# iND83213A register map
Vendor: Indiemicro; Series: Rugby; File version: 1.0
CPU: CM0 r0p1, selectable endian, no MPU, no FPU, 4 interrupt priority bits
Registers are 32-bit, read-write, no defined reset value unless marked. A register's access mark holds for its fields unless they carry their own. Offsets are from the block's base; [hi:lo] are bit positions; {n}, {i} and the like mark numbered series.

## BUCK_INF — BUCK Interface Registers
Base 0x50010500; register names take the prefix BUCK_INF_
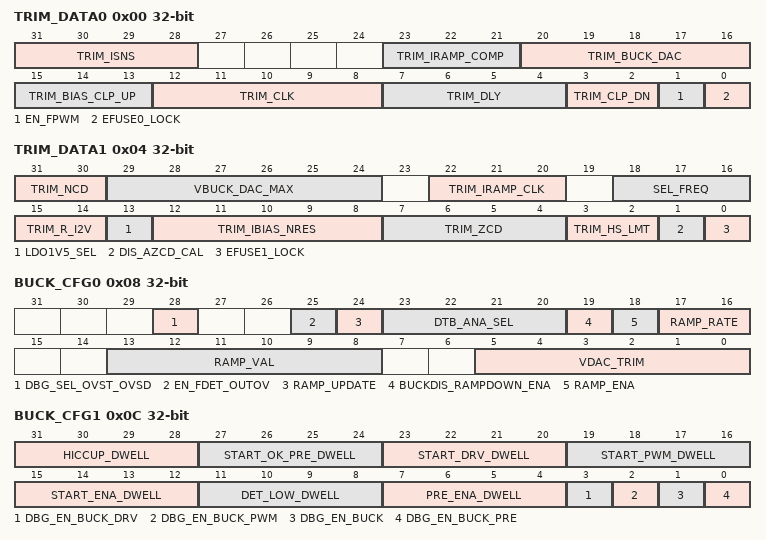
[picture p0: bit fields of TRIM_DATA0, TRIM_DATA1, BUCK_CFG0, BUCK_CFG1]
0x00 TRIM_DATA0
  [31:28] TRIM_ISNS — Trim the offset current of HS current sensor. 0x0: 94.18uA 0x1: 97.51uA 0x2: 100.01uA 0x3: 103.5uA 0x4: 105.5uA 0x5: 108.8uA 0x6: 111.4uA 0x7: 114.7uA 0x8: 71.64uA 0x9: 74.97uA 0xa: 77.6uA 0xb: 80.94uA 0xc: 82.92uA 0xd: 86.25uA 0xe: 88.88uA 0xf: 92.21uA
  [23:21] TRIM_IRAMP_COMP — Trim the current which generates compensation ramp.
  [20:16] TRIM_BUCK_DAC — Trim BUCK dac precision.
  [15:13] TRIM_BIAS_CLP_UP — Trim clamp up bias. 40K ohms clamp up reference resistor add in IR each step.(TBD)
  [12:8] TRIM_CLK — Trim internal BUCK clock(2Mhz/400Khz).
  [7:4] TRIM_DLY — Trim delay time for better accuracy.
  [3:2] TRIM_CLP_DN — Clamp down voltage for VC_EA. 0x0: 400mV 0x1: 500mV 0x2: 600mV 0x3: 700mV
  [1] EN_FPWM — Enable force PWM option.
  [0] EFUSE0_LOCK — The lock signal of eFUSE0. EFUSE0 lock signal can be read out from bitcell at EFUSE0 address 0(after programming). When efuse_lock becomes 1, the programming mode is forbidden and the read data from EFUSE0 can be update to the corresponding registers.
0x04 TRIM_DATA1
  [31:30] TRIM_NCD — Trim the threshold current for NCD. 0x0: -854mA 0x1: -1.434A 0x2: -1.434A 0x3: -1.984A
  [29:24] VBUCK_DAC_MAX — Set maximum output voltage code of BUCK. The BUCK dac code is range from 0 to VBUCK_DAC_MAX.
  [22:20] TRIM_IRAMP_CLK — TRIM_IRAMP_CLK. Trim the bias current send to compensation current ramp module.
  [18:16] SEL_FREQ — Set BUCK clock frequency. 3'b000: 2.125Mhz 3'b001: 1.15Mhz 3'b010: 800Khz 3'b011: 600Khz 3'b100: 490Khz 3'b101: 400Khz others: 2.125Mhz
  [15:14] TRIM_R_I2V — Trim the resistance of I to V sampling circuit. 0x0: 2.5k ohm 0x1: 5k ohm 0x2: 7.5k ohm 0x3: 10k ohm
  [13] LDO1V5_SEL — Select 1p5v ldo type. 1'b0:cap 1p5v LDO. 1'b1:capless 1p5v LDO.
  [12:8] TRIM_IBIAS_NRES — Trim the current which is not related to the process corner of resistance.
  [7:4] TRIM_ZCD — Trim the offset voltage of ZCD comparator. 0x0: -23.45mV 0x1: -21.55mV 0x2: -19.75mV 0x3: -17.85mV 0x4: -15.95mV 0x5: -14.05mV 0x6: -12.15mV 0x7: -10.25mV 0x8: -8.35mV 0x9: -6.45mV 0xa: -4.55mV 0xb: -2.65mV 0xc: -750uV 0xd: 1.15mV 0xe: 3.05mV 0xf: 4.95mV
  [3:2] TRIM_HS_LMT — Trim the current limit of high side NMOS. 0x0: 1.812A 0x1: 2.122A 0x2: 2.422A 0x3: 2.712A
  [1] DIS_AZCD_CAL — Disable auto zcd calculation. 1'b0: enable auto zcd calculation. 1'b1:disable auto zcd calculation.
  [0] EFUSE1_LOCK — The lock signal of eFUSE1. EFUSE1 lock signal can be read out from bitcell at EFUSE1 address 0(after programming). When efuse_lock becomes 1, the programming mode is forbidden and the read data from EFUSE1 can be update to the corresponding registers.
0x08 BUCK_CFG0 — BUCK configuration register0
  [28] DBG_SEL_OVST_OVSD — Control BUCK vout ov threshold in debug mode. 1'b0: 1.1 times of output voltage set value; 1'b1: 2.5V.
  [25] EN_FDET_OUTOV — Force enable VOUT OVP detect in BUCK auto mode. 1'b0: Don't force and VOUT OVP detect comparator will turn off in PS mode. 1'b1: Force enable VOUT OVP detect comparator.
  [24] RAMP_UPDATE — Update VDAC ramp parameters. Set high then set low to launch a ramp update.
  [23:20] DTB_ANA_SEL — select for DTB. Select Analog observed signal to DTB[1]. 0x0: PWM_COMP_OUT 0x1: VBTPORN_ST 0x2: CLP_L_ST 0x3: ZCD_COMP_OUT 0x4: LS_ILMT_ST 0x5: HS_ILMT_ST 0x6: LS_ON_ST 0x7: HS_ON_ST 0x8: VOUT_SHORT_ST 0x9: VOUT_SOFT_OK_ST 0xa: VOUT_OVP_ST 0xb: VIN_UVLO_ST 0xc: VOUT_SD_LOW_N 0xd: PFM_PS 0xe: DTB_RC_PULAE 0xf: CLK_DIV2
  [19] BUCKDIS_RAMPDOWN_ENA — Enable of Ramp down after Core Buck disable. set 1'b1 to enable
  [18] RAMP_ENA — Enable the Ramp feature for VDAC. If set enables the core to ramp the VDAC at a rate set by RAMP_RATE, till the VDAC reach the set code in VDAC_TRIM. if set to '1 the ramped value will be available on VDAC bus, if set to '0 the vdac_trim will be available on VDAC bus
  [17:16] RAMP_RATE — VDAC ramp rate to reach to VDAC_TRIM. When RAMP_ENA is set, the register decides the rate at which the VDAC ramp up/down to reach the set VDAC_TRIM 0x0: 7.8us per step 0x1: 15.6us per step 0x2: 31.2us per step 0x3: 62.4us per step
  [13:8] RAMP_VAL — VDAC ramp start code. The register can only be set in buck debug mode.
  [5:0] VDAC_TRIM — TRIM code for VDAC. Set the VDAC trim code, which decides BUCK output voltage. VBUCK_OUT = (0.15625*VDAC_TRIM) V. The trim code is range from 0 to VBUCK_DAC_MAX. If the trim code is bigger than VBUCK_DAC_MAX, the trim code would be forced to VBUCK_DAC_MAX.
0x0C BUCK_CFG1 — BUCK configuration register1
  [31:28] HICCUP_DWELL — HICCUP Timeout Setting. Timeout wait time = (HICCUP_DWELL + 1)*1ms.
  [27:24] START_OK_PRE_DWELL — START_OK_PRE Timeout Setting. Timeout wait time = (START_OK_PRE_DWELL + 1)*(2^RAMP_RATE)*31.2us.
  [23:20] START_DRV_DWELL — START_DRV Timeout Setting. Timeout wait time = (START_DRV_DWELL + 1)*(2^RAMP_RATE)*7.8us.
  [19:16] START_PWM_DWELL — START_PWM Timeout Setting. Timeout wait time = (START_PWM_DWELL + 1)*7.8us.
  [15:12] START_ENA_DWELL — START_ENA Timeout Setting. Timeout wait time = (START_ENA_DWELL + 1)*7.8us.
  [11:8] DET_LOW_DWELL — DET_LOW Timeout Setting. Timeout wait time = (DET_LOW_DWELL + 1)*1ms.
  [7:4] PRE_ENA_DWELL — PRE_ENA Timeout Setting. Timeout wait time = (PRE_ENA_DWELL + 1)*3.9us.
  [3] DBG_EN_BUCK_DRV — BUCK enable of power stage and driver in debug mode. Set 1'b1 to enable.
  [2] DBG_EN_BUCK_PWM — BUCK enable of PWM Logic in debug mode. Set 1'b1 to enable.
  [1] DBG_EN_BUCK — BUCK control enable in debug mode. Set 1'b1 to enable.
  [0] DBG_EN_BUCK_PRE — Enable V-I and comp_top to detect errors in debug mode. Set 1'b1 to enable.
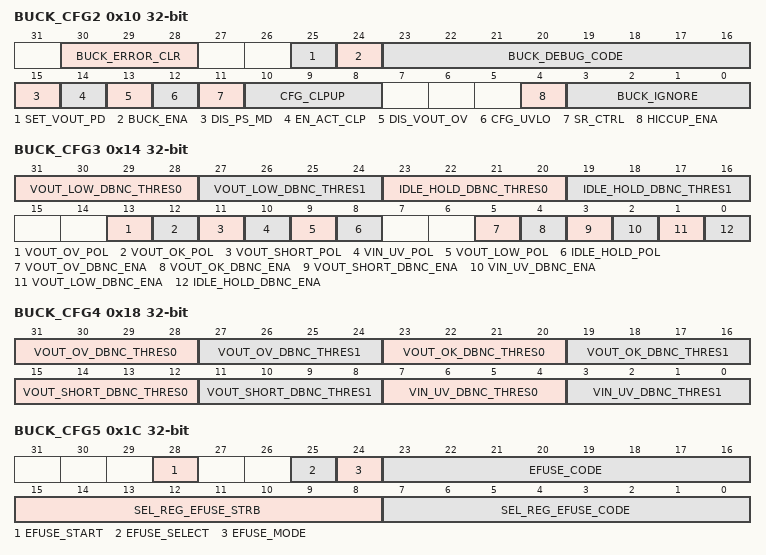
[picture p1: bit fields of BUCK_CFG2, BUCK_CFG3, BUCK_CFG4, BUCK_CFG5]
0x10 BUCK_CFG2 — BUCK configuration register2
  [30:28] BUCK_ERROR_CLR — BUCK error flag clear. Set high then set low to launch a clear operation. BIT[0] : clear error flag: VOUT OVP can't release before BUCK startup BIT[1] : clear error flag: VOUT SHORT can't release after BUCK startup for a while BIT[2] : clear error flag: Vout OK detect fail
  [25] SET_VOUT_PD — SET_VOUT_PD. Set 1 to pull down BUCK output.
  [24] BUCK_ENA — BUCK enable request. Setting this bit to '1 will kickstart the statup sequence for the buck regulator. Setting this bit to '0 will start the off sequence for the buck regulator. Auto clearred if hiccup is disabled & error conditions are encountered.
  [23:16] BUCK_DEBUG_CODE — Code used to set debug mode of BUCK control module. Write 0x2C to this register to enable debug mode. Write any other value to disable the debug mode.
  [15] DIS_PS_MD — Disable pfm_ps_st2 output. 1'b0: the output value of pfm_ps_st2 is valid; 1'b1: the output value of pfm_ps_st2 is set to 0.
  [14] EN_ACT_CLP — Set active clamp down option. 1'b0: enable active clamp down.1'b1: disable active clamp down. The register can only be set in buck debug mode.
  [13] DIS_VOUT_OV — Set VOUT OV option. 1'b0: enable VOUT OV detection.1'b1: disable VOUT OV detection
  [12] CFG_UVLO — Set UVLO threshold. 1'b0: VIN UVLO=4V.1'b1: VIN UVLO=6V
  [11] SR_CTRL — Set slew rate.
  [10:8] CFG_CLPUP — Set clamp up configuration.
  [4] HICCUP_ENA — BUCK HICCUP Enable. Set this bit to high will enable the hiccup control of BUCK FSM.
  [3:0] BUCK_IGNORE — BUCK Status ignore. BIT[0] : ignore vin uvlo detection BIT[1] : ignore vout low detection BIT[2] : ignore vout short detection BIT[3] : ignore vout ok detection
0x14 BUCK_CFG3 — BUCK configuration register3
  [31:28] VOUT_LOW_DBNC_THRES0 — VOUT_LOW debounce threshold from 1 to 0. The deglitch width to detect 0 is from 62.4us to 998.4us.
  [27:24] VOUT_LOW_DBNC_THRES1 — VOUT_LOW debounce threshold from 0 to 1. The deglitch width to detect 1 is from 62.4us to 998.4us.
  [23:20] IDLE_HOLD_DBNC_THRES0 — IDLE_HOLD debounce threshold from 1 to 0. The deglitch width to detect 0 is from 3.9us to 62.4us.
  [19:16] IDLE_HOLD_DBNC_THRES1 — IDLE_HOLD debounce threshold from 0 to 1. The deglitch width to detect 1 is from 3.9us to 62.4us.
  [13] VOUT_OV_POL — The valid level polarity for BUCK VOUT OV signal. 1'b0: the valid level polarity is high. 1'b1: the valid level polarity is low.
  [12] VOUT_OK_POL — The valid level polarity for BUCK VOUT OK signal. 1'b0: the valid level polarity is high. 1'b1: the valid level polarity is low.
  [11] VOUT_SHORT_POL — The valid level polarity for BUCK VOUT SHORT signal. 1'b0: the valid level polarity is high. 1'b1: the valid level polarity is low.
  [10] VIN_UV_POL — The valid level polarity for BUCK VIN UVLO signal. 1'b0: the valid level polarity is high. 1'b1: the valid level polarity is low.
  [9] VOUT_LOW_POL — The valid level polarity for BUCK VOUT LOW signal. 1'b0: the valid level polarity is high. 1'b1: the valid level polarity is low.
  [8] IDLE_HOLD_POL — The valid level polarity for IDLE_HOLD signal. 1'b0: the valid level polarity is high. 1'b1: the valid level polarity is low.
  [5] VOUT_OV_DBNC_ENA — VOUT_OV debounce enable. 1'b0: disable VOUT_OV debounce function. 1'b1: enable VOUT_OV debounce function.
  [4] VOUT_OK_DBNC_ENA — VOUT_OK debounce enable. 1'b0: disable VOUT_OK debounce function. 1'b1: enable VOUT_OK debounce function.
  [3] VOUT_SHORT_DBNC_ENA — VOUT_SHORT debounce enable. 1'b0: disable VOUT_SHORT debounce function. 1'b1: enable VOUT_SHORT debounce function.
  [2] VIN_UV_DBNC_ENA — VIN_UV debounce enable. 1'b0: disable VIN UVLO debounce function. 1'b1: enable VIN UVLO debounce function.
  [1] VOUT_LOW_DBNC_ENA — VOUT_LOW debounce enable. 1'b0: disable VOUT_LOW debounce function. 1'b1: enable VOUT_LOW debounce function.
  [0] IDLE_HOLD_DBNC_ENA — IDLE_HOLD debounce enable. 1'b0: disable IDLE_HOLD debounce function. 1'b1: enable IDLE_HOLD debounce function.
0x18 BUCK_CFG4 — BUCK configuration register4
  [31:28] VOUT_OV_DBNC_THRES0 — VOUT_OV debounce threshold from 1 to 0. The deglitch width to detect 0 is from 7.8us to 124.8us.
  [27:24] VOUT_OV_DBNC_THRES1 — VOUT_OV debounce threshold from 0 to 1. The deglitch width to detect 1 is from 31.2us to 499.2us.
  [23:20] VOUT_OK_DBNC_THRES0 — VOUT_OK debounce threshold from 1 to 0. The deglitch width to detect 0 is from 7.8us to 124.8us.
  [19:16] VOUT_OK_DBNC_THRES1 — VOUT_OK debounce threshold from 0 to 1. The deglitch width to detect 1 is from 7.8us to 124.8us.
  [15:12] VOUT_SHORT_DBNC_THRES0 — VOUT_SHORT debounce threshold from 1 to 0. The deglitch width to detect 0 is from 3.9us to 62.4us.
  [11:8] VOUT_SHORT_DBNC_THRES1 — VOUT_SHORT debounce threshold from 0 to 1. The deglitch width to detect 1 is from 31.2us to 499.2us.
  [7:4] VIN_UV_DBNC_THRES0 — VIN_UV debounce threshold from 1 to 0. The deglitch width to detect 0 is from 249.6us to 3993.6us.
  [3:0] VIN_UV_DBNC_THRES1 — VIN_UV debounce threshold from 0 to 1. The deglitch width to detect 1 is from 3.9us to 62.4us.
0x1C BUCK_CFG5 — BUCK configuration register5
  [28] EFUSE_START — Start EFUSE programming or read/sensing. Set high then set low to launch an EFUSE operation.
  [25] EFUSE_SELECT — EFUSE_SELECT. Select different EFUSE macro(There are two 32 bits EFUSE macros in the chip). 1'b0: EFUSE macro0; 1'b1: EFUSE macro1.
  [24] EFUSE_MODE — EFUSE_MODE. Select EFUSE operation mode.1'b0: read/sensing mode; 1'b1: programming mode.
  [23:16] EFUSE_CODE — Code used to set EFUSE configurate enable. Write 0xB9 to this register to enable EFUSE configuration. Write any other value to disable EFUSE configuration.
  [15:8] SEL_REG_EFUSE_STRB — The register is used to set byte strobe signal to select trim data source when SEL_REG_EFUSE_CODE is set to 0xE2. When SEL_REG_EFUSE_CODE is set to 0xE2 and the corresponding bit is set to high, the byte lane of trim data would come from registers. SEL_REG_EFUSE_STRB[0] corresponds to efuse0 data[ 7: 0]. SEL_REG_EFUSE_STRB[1] corresponds to efuse0 data[15: 8]. SEL_REG_EFUSE_STRB[2] corresponds to efuse0 data[23:16]. SEL_REG_EFUSE_STRB[3] corresponds to efuse0 data[31:24]. SEL_REG_EFUSE_STRB[4] corresponds to efuse1 data[ 7: 0]. SEL_REG_EFUSE_STRB[5] corresponds to efuse1 data[15: 8]. SEL_REG_EFUSE_STRB[6] corresponds to efuse1 data[23:16]. SEL_REG_EFUSE_STRB[7] corresponds to efuse1 data[31:24].
  [7:0] SEL_REG_EFUSE_CODE — Code used to set BUCK trim data sources. Write 0xE2 to this register to select BUCK trim data from registers. Write any other value to select BUCK trim data from EFUSE.
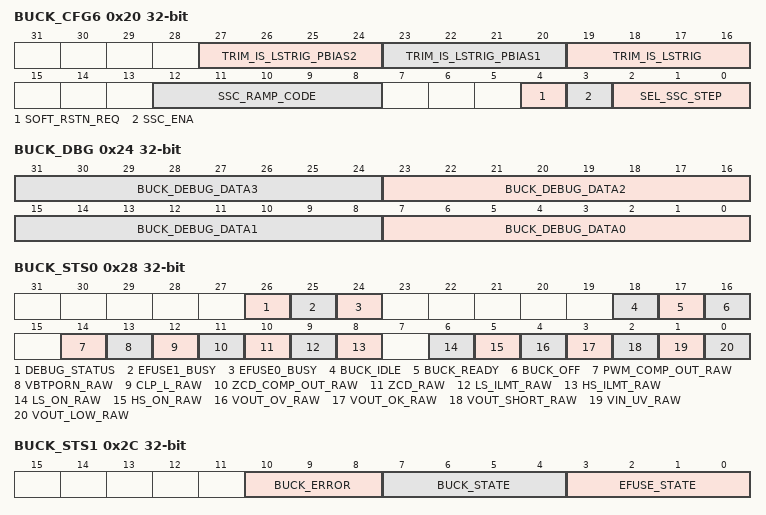
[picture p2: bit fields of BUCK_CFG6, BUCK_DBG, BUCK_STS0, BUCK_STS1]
0x20 BUCK_CFG6 — BUCK configuration register6
  [27:24] TRIM_IS_LSTRIG_PBIAS2 — Trim the upper limit of the curve of LS current limit vs VEA-VCP_L.
  [23:20] TRIM_IS_LSTRIG_PBIAS1 — Trim the upper limit of the curve of LS current limit vs VEA-VCP_L.
  [19:16] TRIM_IS_LSTRIG — Trim the derivative of the curve of LS current limit vs VEA-VCP_L.
  [12:8] SSC_RAMP_CODE — Set SSC ramp code in debug mode. The register can directly control buck clock freq.
  [4] SOFT_RSTN_REQ — Generate a pulse used to reset BUCK 5V logic. Pull up and then pull down to generate a pulse.
  [3] SSC_ENA — SSC enable.
  [2:0] SEL_SSC_STEP — Set step period used in SSC. 3'b000: 8 steps per period . 3'b001: 4 steps per period . 3'b010: 2 steps per period . 3'b011: 1 steps per period . 3'b100: 1 step per 2 periods . 3'b101: 1 step per 3 periods . 3'b110: 1 step per 4 periods . 3'b111: 1 step per 5 periods .
0x24 BUCK_DBG — BUCK debug register
  [8n+7:8n] BUCK_DEBUG_DATA{n} (n=0..3) — Debug signal, only can be set in debug mode.
0x28 BUCK_STS0 — BUCK status register0
  [26] DEBUG_STATUS ro — DEBUG_STATUS. Status of Debug
  [25] EFUSE1_BUSY ro — EFUSE1 busy signal. When EFUSE_BUSY1 becomes 1, EFUSE1 is working in read(sensing)/programming operation mode.
  [24] EFUSE0_BUSY ro — EFUSE0 busy signal. When EFUSE_BUSY0 becomes 1, EFUSE0 is working in read(sensing)/programming operation mode.
  [18] BUCK_IDLE ro — Status of Buck idle. When BUCK_IDLE becomes 1, The FSM of BUCK is located in IDLE state.
  [17] BUCK_READY ro — Status of Buck ready. When BUCK_READY becomes 1, The FSM of BUCK is located in START_OK/ENA_L state.
  [16] BUCK_OFF ro — Status of Buck off. When BUCK_OFF becomes 1, The FSM of BUCK is located in IDLE/HICCUP/PRE_ENA/DET_VIN/DET_LOW/ENA_L_ERR state.
  [14] PWM_COMP_OUT_RAW ro — Raw status of Buck PWM Comparator output.
  [13] VBTPORN_RAW ro — Raw status of voltage for VBT.
  [12] CLP_L_RAW ro — Raw status of clamp low for EA.
  [11] ZCD_COMP_OUT_RAW ro — Raw status of ZCD comparator output.
  [10] ZCD_RAW ro — Raw status of Buck Low Side NMOS is reach to zero current.
  [9] LS_ILMT_RAW ro — Raw status of Buck Low Side NMOS Over Current.
  [8] HS_ILMT_RAW ro — Raw status of Buck High Side NMOS Over Current.
  [6] LS_ON_RAW ro — Raw status of Buck Low Side NMOS ON.
  [5] HS_ON_RAW ro — Raw status of Buck High Side NMOS ON.
  [4] VOUT_OV_RAW ro — Raw status of Buck Output over-voltage.
  [3] VOUT_OK_RAW ro — Raw status of Buck Output voltage OK.
  [2] VOUT_SHORT_RAW ro — Raw status of Buck Output short.
  [1] VIN_UV_RAW ro — Raw status of Buck Input UVLO.
  [0] VOUT_LOW_RAW ro — Raw status of Buck output low.
0x2C BUCK_STS1 — BUCK status register1
  [10:8] BUCK_ERROR ro — BUCK error flag. bit[0] : VOUT OVP can't release before BUCK startup. bit[1] : VOUT SHORT can't release after BUCK startup for a while. bit[2] : VOUT OK detect fail.
  [7:4] BUCK_STATE ro — BUCK FSM state. BUCK FSM state, which can be used for debug. 0x0: IDLE 0x1: HICCUP 0x2: PRE_ENA 0x3: DET_VIN 0x4: DET_LOW 0x5: START_ENA 0x6: START_PWM 0x7: START_DRV 0x8: START_OK_PRE 0x9: START_OK 0xa: ENA_L 0xb: ENA_L_ERR
  [3:0] EFUSE_STATE ro — EFUSE FSM state. EFUSE FSM state, which can be used for debug. 0x0: IDLE 0x1: PG_PSTP1 0x2: PG_PSTP2 0x3: PG_PAS 0x4: PG_WDH 0x5: PG_PAH 0x6: PG_PHD2 0x7: PG_PHD1 0x8: RS_CSSTP 0x9: RS_PRSTP 0xa: RS_PRHD 0xb: RS_SNHD 0xc: RS_CSHD
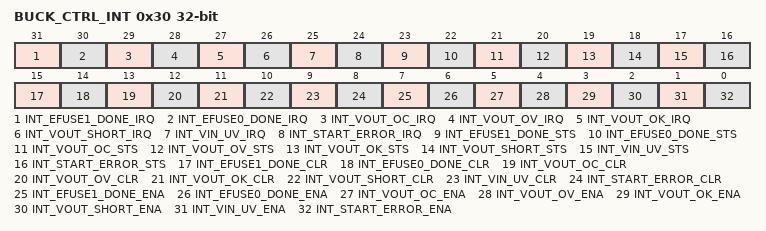
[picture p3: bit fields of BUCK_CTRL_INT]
0x30 BUCK_CTRL_INT — BUCK control & interrupt register
  [31] INT_EFUSE1_DONE_IRQ ro — EFUSE macro1 done interrupt activity.
  [30] INT_EFUSE0_DONE_IRQ ro — EFUSE macro0 done interrupt activity.
  [29] INT_VOUT_OC_IRQ ro — Vout over-current interrupt activity.
  [28] INT_VOUT_OV_IRQ ro — Vout over-voltage interrupt activity.
  [27] INT_VOUT_OK_IRQ ro — Vout soft start OK interrupt activity.
  [26] INT_VOUT_SHORT_IRQ ro — Vout short interrupt activity.
  [25] INT_VIN_UV_IRQ ro — Vin under-voltage interrupt activity.
  [24] INT_START_ERROR_IRQ ro — BUCK start error interrupt activity.
  [23] INT_EFUSE1_DONE_STS ro — EFUSE macro1 done interrupt status.
  [22] INT_EFUSE0_DONE_STS ro — EFUSE macro0 done interrupt status.
  [21] INT_VOUT_OC_STS ro — Vout over-current interrupt status.
  [20] INT_VOUT_OV_STS ro — Vout over-voltage interrupt status.
  [19] INT_VOUT_OK_STS ro — Vout soft start OK interrupt status.
  [18] INT_VOUT_SHORT_STS ro — Vout short interrupt status.
  [17] INT_VIN_UV_STS ro — Vin under-voltage interrupt status.
  [16] INT_START_ERROR_STS ro — BUCK start error interrupt status.
  [15] INT_EFUSE1_DONE_CLR wo — EFUSE macro1 done interrupt clear.
  [14] INT_EFUSE0_DONE_CLR wo — EFUSE macro0 done interrupt clear.
  [13] INT_VOUT_OC_CLR wo — Vout over-current interrupt clear.
  [12] INT_VOUT_OV_CLR wo — Vout over-voltage interrupt clear.
  [11] INT_VOUT_OK_CLR wo — Vout soft start OK interrupt clear.
  [10] INT_VOUT_SHORT_CLR wo — Vout short interrupt clear.
  [9] INT_VIN_UV_CLR wo — Vin under-voltage interrupt clear.
  [8] INT_START_ERROR_CLR wo — BUCK start error interrupt clear.
  [7] INT_EFUSE1_DONE_ENA — EFUSE macro1 done interrupt enable.
  [6] INT_EFUSE0_DONE_ENA — EFUSE macro0 done interrupt enable.
  [5] INT_VOUT_OC_ENA — Vout over-current interrupt enable.
  [4] INT_VOUT_OV_ENA — Vout over-voltage interrupt enable.
  [3] INT_VOUT_OK_ENA — Vout soft start OK interrupt enable.
  [2] INT_VOUT_SHORT_ENA — Vout short interrupt enable.
  [1] INT_VIN_UV_ENA — Vin under-voltage interrupt enable.
  [0] INT_START_ERROR_ENA — BUCK start error interrupt enable.
